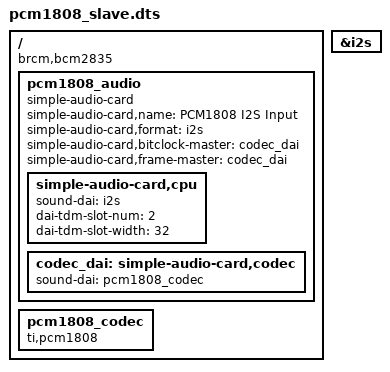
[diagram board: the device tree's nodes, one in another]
/dts-v1/;
/plugin/;

/ {
    compatible = "brcm,bcm2835";

    fragment@0 {
        target = <&i2s>;
        __overlay__ {
            status = "okay";
            #sound-dai-cells = <0>;
        };
    };

    fragment@1 {
        target-path = "/";
        __overlay__ {
            pcm1808_audio: pcm1808_audio {
                compatible = "simple-audio-card";
                simple-audio-card,name = "PCM1808 I2S Input";
                simple-audio-card,format = "i2s";

                simple-audio-card,bitclock-master = <&codec_dai>;  
                simple-audio-card,frame-master    = <&codec_dai>;

                simple-audio-card,cpu {
                    sound-dai = <&i2s>;
                    dai-tdm-slot-num = <2>;
                    dai-tdm-slot-width = <32>;
                };

                codec_dai: simple-audio-card,codec {
                    sound-dai = <&pcm1808_codec>;
                };
            };

            pcm1808_codec: pcm1808_codec {
                compatible = "ti,pcm1808";
                #sound-dai-cells = <0>;
            };
        };
    };
};
